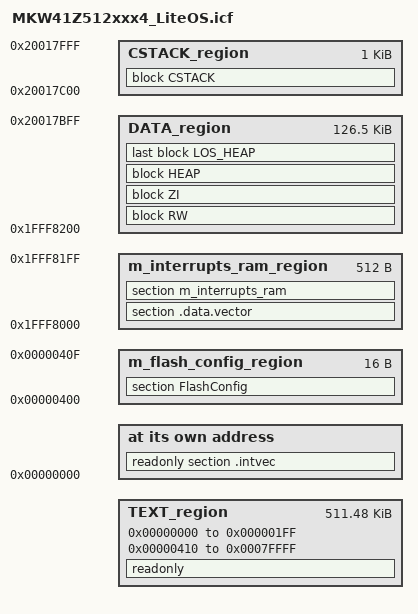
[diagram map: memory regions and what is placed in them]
/*
** ###################################################################
**     Processors:          MKW41Z512CAT4
**                          MKW41Z512VHT4
**
**     Compiler:            IAR ANSI C/C++ Compiler for ARM
**     Reference manual:    MKW41Z512RM Rev. 0.1, 04/2016
**     Version:             rev. 1.0, 2015-09-23
**     Build:               b170214
**
**     Abstract:
**         Linker file for the IAR ANSI C/C++ Compiler for ARM
**
**     Copyright 2016 Freescale Semiconductor, Inc.
**     Copyright 2016-2017 NXP
**     Redistribution and use in source and binary forms, with or without modification,
**     are permitted provided that the following conditions are met:
**
**     o Redistributions of source code must retain the above copyright notice, this list
**       of conditions and the following disclaimer.
**
**     o Redistributions in binary form must reproduce the above copyright notice, this
**       list of conditions and the following disclaimer in the documentation and/or
**       other materials provided with the distribution.
**
**     o Neither the name of the copyright holder nor the names of its
**       contributors may be used to endorse or promote products derived from this
**       software without specific prior written permission.
**
**     THIS SOFTWARE IS PROVIDED BY THE COPYRIGHT HOLDERS AND CONTRIBUTORS "AS IS" AND
**     ANY EXPRESS OR IMPLIED WARRANTIES, INCLUDING, BUT NOT LIMITED TO, THE IMPLIED
**     WARRANTIES OF MERCHANTABILITY AND FITNESS FOR A PARTICULAR PURPOSE ARE
**     DISCLAIMED. IN NO EVENT SHALL THE COPYRIGHT HOLDER OR CONTRIBUTORS BE LIABLE FOR
**     ANY DIRECT, INDIRECT, INCIDENTAL, SPECIAL, EXEMPLARY, OR CONSEQUENTIAL DAMAGES
**     (INCLUDING, BUT NOT LIMITED TO, PROCUREMENT OF SUBSTITUTE GOODS OR SERVICES;
**     LOSS OF USE, DATA, OR PROFITS; OR BUSINESS INTERRUPTION) HOWEVER CAUSED AND ON
**     ANY THEORY OF LIABILITY, WHETHER IN CONTRACT, STRICT LIABILITY, OR TORT
**     (INCLUDING NEGLIGENCE OR OTHERWISE) ARISING IN ANY WAY OUT OF THE USE OF THIS
**     SOFTWARE, EVEN IF ADVISED OF THE POSSIBILITY OF SUCH DAMAGE.
**
**     http:                 www.nxp.com
**     mail:                 support@nxp.com
**
** ###################################################################
*/

define symbol __LITEOS_RAM_VECTOR__ = 0x20017FFF;

define symbol __ram_vector_table_size__ =  isdefinedsymbol(__ram_vector_table__) ? 0x00000200 : 0;
define symbol __ram_vector_table_offset__ =  isdefinedsymbol(__ram_vector_table__) ? 0x000001FF : 0;

define symbol m_interrupts_start       = 0x00000000;
define symbol m_interrupts_end         = 0x000001FF;

define symbol m_flash_config_start     = 0x00000400;
define symbol m_flash_config_end       = 0x0000040F;

define symbol m_text_start             = 0x00000410;
define symbol m_text_end               = 0x0007FFFF;

if (isdefinedsymbol(__LITEOS_RAM_VECTOR__)) {
  define symbol m_interrupts_ram_start   = 0x1FFF8000;
  define symbol m_interrupts_ram_end     = 0x1FFF8000 + 0x000001FF;
} else {
  define symbol m_interrupts_ram_start   = 0x1FFF8000;
  define symbol m_interrupts_ram_end     = 0x1FFF8000 + __ram_vector_table_offset__;
}

if (isdefinedsymbol(__LITEOS_RAM_VECTOR__)) {
  define symbol m_data_start             = m_interrupts_ram_start + 0x00000200;
  define symbol m_data_end               = 0x20017FFF;
} else {
  define symbol m_data_start             = m_interrupts_ram_start + __ram_vector_table_size__;
  define symbol m_data_end               = 0x20017FFF;
}

/* Sizes */
if (isdefinedsymbol(__stack_size__)) {
  define symbol __size_cstack__        = __stack_size__;
} else {
  define symbol __size_cstack__        = 0x0400;
}

if (isdefinedsymbol(__heap_size__)) {
  define symbol __size_heap__          = __heap_size__;
} else {
  define symbol __size_heap__          = 0x0400;
}

define symbol __ICFEDIT_size_los_min_heap__  = 0x400;

define exported symbol __VECTOR_TABLE  = m_interrupts_start;
define exported symbol __VECTOR_RAM    = isdefinedsymbol(__ram_vector_table__) ? m_interrupts_ram_start : m_interrupts_start;
define exported symbol __RAM_VECTOR_TABLE_SIZE = __ram_vector_table_size__;
define exported symbol __LITEOS_HEAP_END__ = m_data_end-__size_cstack__;

define memory mem with size = 4G;
define region m_flash_config_region = mem:[from m_flash_config_start to m_flash_config_end];
define region TEXT_region = mem:[from m_interrupts_start to m_interrupts_end]
                          | mem:[from m_text_start to m_text_end];
define region DATA_region = mem:[from m_data_start to m_data_end-__size_cstack__];
define region CSTACK_region = mem:[from m_data_end-__size_cstack__+1 to m_data_end];
define region m_interrupts_ram_region = mem:[from m_interrupts_ram_start to m_interrupts_ram_end];

define block CSTACK    with alignment = 8, size = __size_cstack__   { };
define block HEAP      with alignment = 8, size = __size_heap__     { };
define block RW        { readwrite };
define block ZI        { zi };
define block LOS_HEAP  with alignment = 8, size = __ICFEDIT_size_los_min_heap__ { };

initialize by copy { readwrite, section .textrw };
do not initialize  { section .noinit };

place at address mem: m_interrupts_start    { readonly section .intvec };
place in m_flash_config_region              { section FlashConfig };
place in TEXT_region                        { readonly };
place in DATA_region                        { block RW };
place in DATA_region                        { block ZI };
place in DATA_region                        { block HEAP, last block LOS_HEAP };
place in CSTACK_region                      { block CSTACK };
if (isdefinedsymbol(__LITEOS_RAM_VECTOR__)) {
  place in m_interrupts_ram_region            { section .data.vector };
} else {
  place in m_interrupts_ram_region            { section m_interrupts_ram };
}

